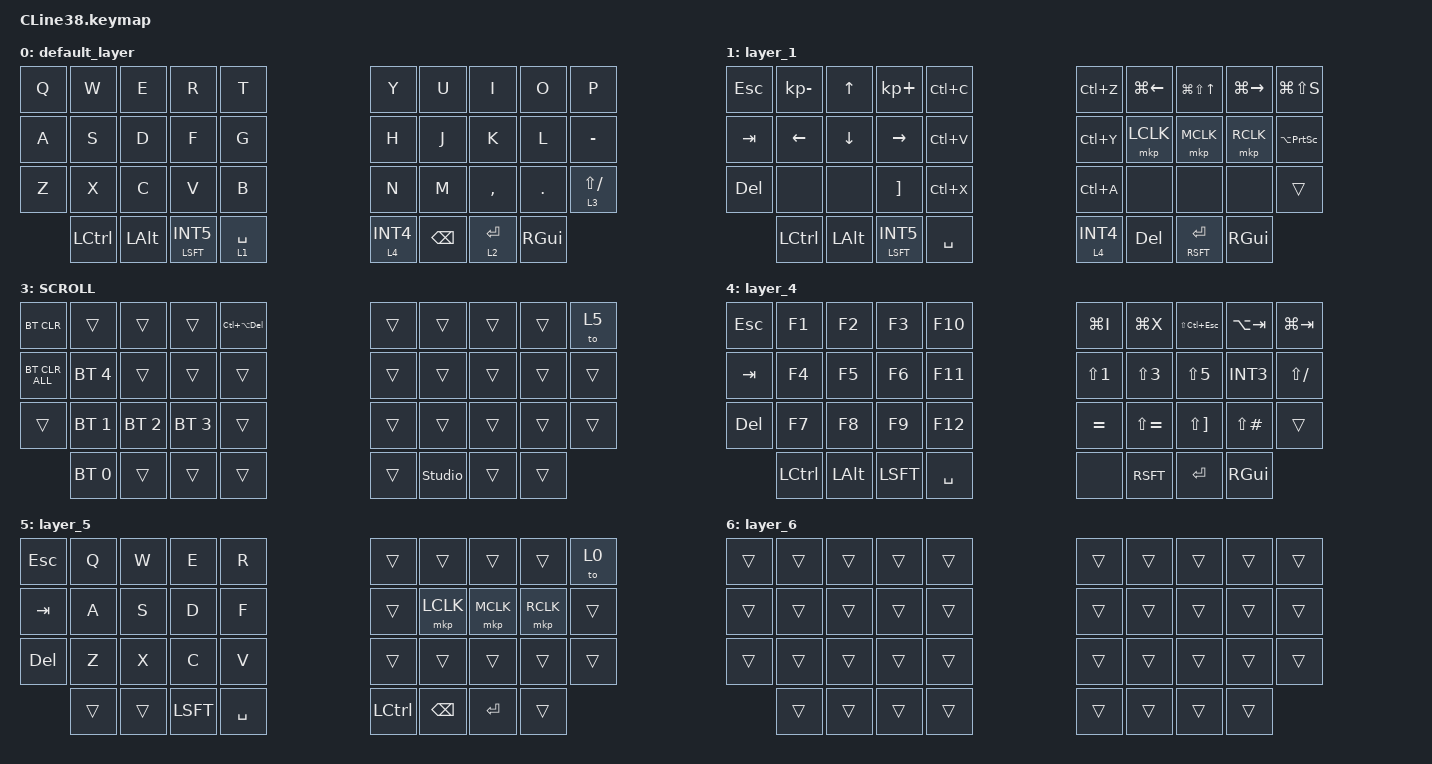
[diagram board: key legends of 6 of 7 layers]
#include <input/processors.dtsi>
#include <dt-bindings/zmk/input_transform.h>
#include <zephyr/dt-bindings/input/input-event-codes.h>
#include <behaviors.dtsi>
#include <behaviors/runtime_macro.dtsi>
#include <dt-bindings/zmk/bt.h>
#include <dt-bindings/zmk/keys.h>
#include <dt-bindings/zmk/pointing.h>

&mt {
    flavor = "balanced";
    quick-tap-ms = <0>;
};

/ {
combos {
    compatible = "zmk,combos";

    // 16 + 17 = Left Click
    left_click {
        bindings = <&mkp LCLK>;
        key-positions = <16 17>;
    };

    // 17 + 18 = Right Click
    right_click {
        bindings = <&mkp RCLK>;
        key-positions = <17 18>;
    };

    // 16 + 18 = Middle Click
    middle_click {
        bindings = <&mkp MCLK>;
        key-positions = <16 18>;
    };

    // 6 + 7 = Alt + Left
    alt_left {
        bindings = <&kp LA(LEFT)>;
        key-positions = <6 7>;
    };

    // 7 + 8 = Alt + Right
    alt_right {
        bindings = <&kp LA(RIGHT)>;
        key-positions = <7 8>;
    };

    tab {
           bindings = <&kp TAB>;
            key-positions = <12 13>;
      };

    shift_tab {
           bindings = <&kp LS(TAB)>;
           key-positions = <11 12>;
      };

    Esc {
           bindings = <&kp ESC>;
           key-positions = <2 3>;
      };
};

    macros {
        to_layer_0: to_layer_0 {
            compatible = "zmk,behavior-macro-one-param";
            #binding-cells = <1>;
            bindings = <&to 0 &macro_param_1to1 &kp MACRO_PLACEHOLDER>;
            label = "TO_LAYER_0";
        };
    };

    behaviors {
        lt_to_layer_0: lt_to_layer_0 {
            compatible = "zmk,behavior-hold-tap";
            label = "LAYER_TAP_TO_0";
            bindings = <&mo>, <&to_layer_0>;

            #binding-cells = <2>;
            tapping-term-ms = <200>;
        };
    };

    keymap {
        compatible = "zmk,keymap";

        default_layer {
            bindings = <
&kp Q       &kp W       &kp E     &kp R           &kp T                                   &kp Y      &kp U   &kp I       &kp O       &kp P
&kp A       &kp S       &kp D     &kp F           &kp G                                   &kp H      &kp J   &kp K       &kp L       &kp MINUS
&kp Z       &kp X       &kp C     &kp V           &kp B                                   &kp N      &kp M   &kp COMMA   &kp DOT     &lt 3 LS(SLASH)
            &kp LCTRL   &kp LALT  &mt LSFT INT5   &lt 1 SPACE   &lt 4 INT4     &kp BSPC   &lt 2 RET                      &kp RGUI
            >;
        };

        
        layer_1 {
            bindings = <
&kp ESC     &kp KP_MINUS   &kp UP    &kp KP_PLUS     &kp LC(C)                             &kp LC(Z)    &kp LG(LEFT)   &kp LG(LS(UP))   &kp LG(RIGHT)   &kp LG(LS(S))
&kp TAB     &kp LEFT       &kp DOWN  &kp RIGHT       &kp LC(V)                             &kp LC(Y)    &mkp LCLK      &mkp MCLK        &mkp RCLK       &kp LA(PRINTSCREEN)
&kp DEL     &none          &none     &kp RBKT        &kp LC(X)                             &kp LC(A)    &none          &none            &none           &trans
            &kp LCTRL      &kp LALT  &mt LSFT INT5   &kp SPACE   &lt 4 INT4      &kp DEL   &mt RSFT RET                                 &kp RGUI
            >;
        };


        MOUSE {
            bindings = <
&kp LS(SINGLE_QUOTE)   &kp NUMBER_1   &kp NUMBER_2   &kp NUMBER_3   &kp NUMBER_0                 &kp SEMI           &kp SINGLE_QUOTE   &kp LG(LC(LEFT))  &kp LG(LC(RIGHT))   &kp LG(E)
&kp LS(SEMI)           &kp NUMBER_4   &kp NUMBER_5   &kp NUMBER_6   &kp DOT                      &kp LS(NUMBER_6)   &kp LS(NUMBER_2)   &kp LBKT          &kp LS(INT1)        &kp LG(T)
&kp MINUS              &kp NUMBER_7   &kp NUMBER_8   &kp NUMBER_9   &kp SLASH                    &kp LS(NUMBER_4)   &kp LS(NUMBER_7)   &kp LS(NUMBER_8)  &kp LS(NUMBER_9)    &trans
                       &kp LCTRL      &kp LALT       &mt LSFT DEL   &kp RET           &kp BSPC   &none                                                   &kp RGUI
            >;
        };


        SCROLL {
            bindings = <
&bt BT_CLR       &trans         &trans         &trans         &kp LC(LA(DEL))                          &trans   &trans   &trans   &trans   &to 5
&bt BT_CLR_ALL   &bt BT_SEL 4   &trans         &trans         &trans                                &trans   &trans   &trans   &trans   &trans
&trans           &bt BT_SEL 1   &bt BT_SEL 2   &bt BT_SEL 3   &trans                                &trans   &trans   &trans   &trans   &trans
                 &bt BT_SEL 0   &trans         &trans         &trans   &trans      &studio_unlock   &trans                     &trans     
            >;
        };


        layer_4 {
            bindings = <
&kp ESC  &kp F1     &kp F2     &kp F3     &kp F10                         &kp LG(I)          &kp LG(X)          &kp LS(LC(ESC))    &kp LA(TAB)   &kp LG(TAB)
&kp TAB  &kp F4     &kp F5     &kp F6     &kp F11                         &kp LS(NUMBER_1)   &kp LS(NUMBER_3)   &kp LS(NUMBER_5)   &kp INT3      &kp LS(SLASH)
&kp DEL  &kp F7     &kp F8     &kp F9     &kp F12                         &kp EQUAL          &kp LS(EQUAL)      &kp LS(RBKT)       &kp LS(HASH)  &trans
         &kp LCTRL  &kp LALT   &kp LSFT   &kp SPACE   &none    &kp RSFT   &kp RET                                                  &kp RGUI
            >;
        };


        layer_5 {
            bindings = <
&kp ESC   &kp Q    &kp W    &kp E      &kp R                                 &trans   &trans      &trans      &trans      &to 0
&kp TAB   &kp A    &kp S    &kp D      &kp F                                 &trans   &mkp LCLK   &mkp MCLK   &mkp RCLK   &trans
&kp DEL   &kp Z    &kp X    &kp C      &kp V                                 &trans   &trans      &trans      &trans      &trans
          &trans   &trans   &kp LSFT   &kp SPACE   &kp LCTRL      &kp BSPC   &kp RET                          &trans       
            >;
        };


        layer_6 {
            bindings = <
&trans   &trans   &trans   &trans   &trans                        &trans   &trans   &trans   &trans   &trans
&trans   &trans   &trans   &trans   &trans                        &trans   &trans   &trans   &trans   &trans
&trans   &trans   &trans   &trans   &trans                        &trans   &trans   &trans   &trans   &trans
         &trans   &trans   &trans   &trans   &trans      &trans   &trans                     &trans
            >;
        };
    };
};
